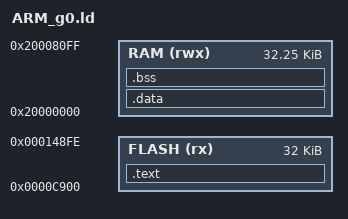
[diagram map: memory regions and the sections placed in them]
MEMORY
{
    FLASH (rx) : ORIGIN = 0x000C900, LENGTH = 0x00007FFF
    RAM (rwx) : ORIGIN = 0x20000000, LENGTH = 0x00008100
}

SECTIONS
{
    .text :
    {
        _start_text = .;
        KEEP(*(.isr_vector))
        *(.init)
        *(.fini)
        *(.text*)
        *(.rodata*)
        . = ALIGN(4);
        _end_text = .;
    } > FLASH

    _stored_data = .;

    .data : AT (_stored_data)
    {
        _start_data = .;
        KEEP(*(.data*))
        . = ALIGN(4);
        _end_data = .;
    } > RAM

    .bss :
    {
        _start_bss = .;
        *(.bss*)
        *(COMMON)
        . = ALIGN(4);
        _end_bss = .;
        _end = .;
    } > RAM
}

PROVIDE(_start_heap = _end);
PROVIDE(_end_stack  = ORIGIN(RAM) + LENGTH(RAM));
